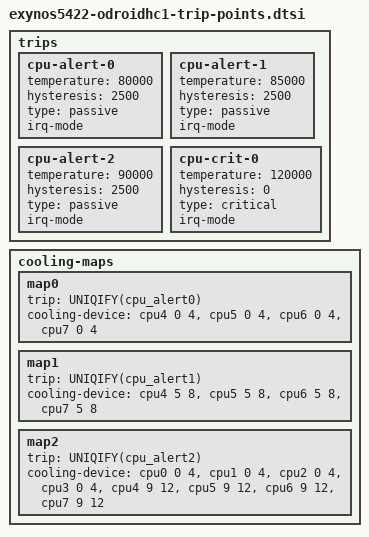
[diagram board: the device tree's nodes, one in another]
/*
 * Device tree sources for default OdroidXU3/Exynos5422 thermal zone definition
 *
 * Copyright (c) 2015 Lukasz Majewski <l.majewski@samsung.com>
 *						Anand Moon <linux.amoon@gmail.com>
 *
 * This program is free software; you can redistribute it and/or modify
 * it under the terms of the GNU General Public License version 2 as
 * published by the Free Software Foundation.
 *
 */

#define _TOKENPASTE(x, y) x ## y
#define TOKENPASTE(x, y) _TOKENPASTE(x, y)
#define UNIQIFY(label) TOKENPASTE(label, CPU_THERMAL_ZONE_NUM)

			trips {
				UNIQIFY(cpu_alert0): cpu-alert-0 {
					temperature = <80000>; /* millicelsius */
					hysteresis = <2500>; /* millicelsius */
					type = "passive";
					irq-mode;
				};
				UNIQIFY(cpu_alert1): cpu-alert-1 {
					temperature = <85000>; /* millicelsius */
					hysteresis = <2500>; /* millicelsius */
					type = "passive";
					irq-mode;
				};
				UNIQIFY(cpu_alert2): cpu-alert-2 {
					temperature = <90000>; /* millicelsius */
					hysteresis = <2500>; /* millicelsius */
					type = "passive";
					irq-mode;
				};
				UNIQIFY(cpu_criti0): cpu-crit-0 {
					temperature = <120000>; /* millicelsius */
					hysteresis = <0>; /* millicelsius */
					type = "critical";
					irq-mode;
				};
			};
			cooling-maps {
				/*
				 * When reaching cpu_alert0, reduce A15 cores by 4 steps.
				 * The top frequency causes high thermals on multithreaded workloads
				 * so better performance is gained by managing it out early.
				 */
				map0 {
					trip = <&UNIQIFY(cpu_alert0)>;
					cooling-device = <&cpu4 0 4>,
							 <&cpu5 0 4>,
							 <&cpu6 0 4>,
							 <&cpu7 0 4>;
				};
				/*
				* When reaching cpu_alert1, reduce A15 cores by 4 more steps
				* to further manage the performance level while keeping
				* thermals under control.
				*/
				map1 {
					trip = <&UNIQIFY(cpu_alert1)>;
					cooling-device = <&cpu4 5 8>,
							 <&cpu5 5 8>,
							 <&cpu6 5 8>,
							 <&cpu7 5 8>;
				};
				/*
				 * When reaching cpu_alert2, reduce all CPUs to ensure thermal
				 * safety. A7 cores don't produce much thermal load so they are
				 * reduced less to optimise performance.
				 */
				map2 {
					trip = <&UNIQIFY(cpu_alert2)>;
					cooling-device = <&cpu0 0 4>,
							 <&cpu1 0 4>,
							 <&cpu2 0 4>,
							 <&cpu3 0 4>,
							 <&cpu4 9 12>,
							 <&cpu5 9 12>,
							 <&cpu6 9 12>,
							 <&cpu7 9 12>;
				};
			};
